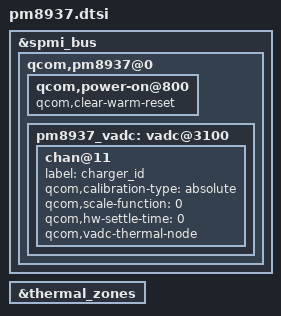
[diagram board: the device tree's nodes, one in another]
/*
 * Copyright (c) 2015-2019, The Linux Foundation. All rights reserved.
 *
 * This program is free software; you can redistribute it and/or modify
 * it under the terms of the GNU General Public License version 2 and
 * only version 2 as published by the Free Software Foundation.
 *
 * This program is distributed in the hope that it will be useful,
 * but WITHOUT ANY WARRANTY; without even the implied warranty of
 * MERCHANTABILITY or FITNESS FOR A PARTICULAR PURPOSE.  See the
 * GNU General Public License for more details.
 */

&spmi_bus {
	qcom,pm8937@0 {
		qcom,power-on@800 {
			qcom,clear-warm-reset;
		};

		pm8937_vadc: vadc@3100 {
			chan@11 {
				label = "charger_id";
				qcom,calibration-type = "absolute";
				qcom,scale-function = <0>;
				qcom,hw-settle-time = <0>;
				qcom,vadc-thermal-node;
			};
		};
	};
};

&thermal_zones {
	/delete-node/ pa-therm1-adc;
};
